# AT32UC3L0128 device description
Architecture: AVR32_UC3; Family: AVR UC3
Registers are 32-bit, read-write, reset 0x0 unless marked. A register's access mark holds for its fields unless they carry their own. Offsets are from the block's base; [hi:lo] are bit positions; {n}, {i} and the like mark numbered series; 'fields as' and 'values as' point back to an identical list.

## SCIF — System Control Interface
Instances: SCIF 0xffff1800
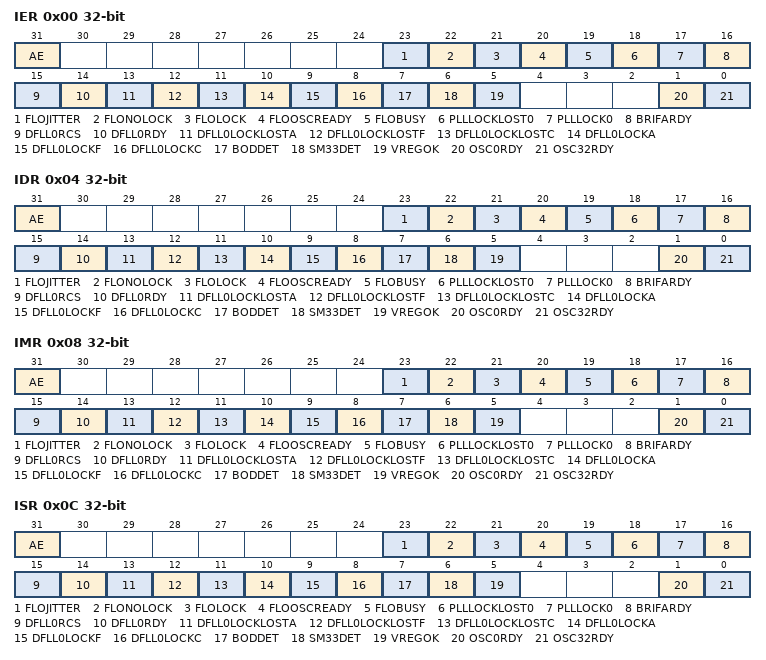
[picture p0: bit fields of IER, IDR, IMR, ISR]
0x00 IER wo — Interrupt Enable Register
  [31] AE, [23] FLOJITTER, [22] FLONOLOCK, [21] FLOLOCK, [20] FLOOSCREADY, [19] FLOBUSY, [18] PLLLOCKLOST0, [17] PLLLOCK0, [16] BRIFARDY, [15] DFLL0RCS, [14] DFLL0RDY, [13] DFLL0LOCKLOSTA, [12] DFLL0LOCKLOSTF, [11] DFLL0LOCKLOSTC, [10] DFLL0LOCKA, [9] DFLL0LOCKF, [8] DFLL0LOCKC, [7] BODDET, [6] SM33DET, [5] VREGOK, [1] OSC0RDY, [0] OSC32RDY
0x04 IDR wo — Interrupt Disable Register
  fields as IER
0x08 IMR ro — Interrupt Mask Register
  fields as IER
0x0C ISR ro — Interrupt Status Register
  fields as IER
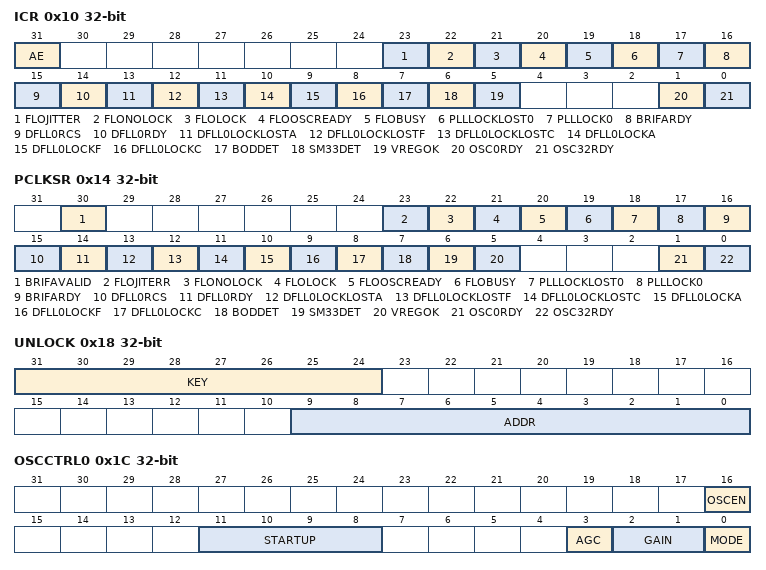
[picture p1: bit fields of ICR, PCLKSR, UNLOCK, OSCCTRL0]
0x10 ICR wo — Interrupt Clear Register
  fields as IER
0x14 PCLKSR ro — Power and Clocks Status Register
  [30] BRIFAVALID, [23] FLOJITERR, [22] FLONOLOCK, [21] FLOLOCK, [20] FLOOSCREADY, [19] FLOBUSY, [18] PLLLOCKLOST0, [17] PLLLOCK0, [16] BRIFARDY, [15] DFLL0RCS, [14] DFLL0RDY, [13] DFLL0LOCKLOSTA, [12] DFLL0LOCKLOSTF, [11] DFLL0LOCKLOSTC, [10] DFLL0LOCKA, [9] DFLL0LOCKF, [8] DFLL0LOCKC, [7] BODDET, [6] SM33DET, [5] VREGOK, [1] OSC0RDY, [0] OSC32RDY
0x18 UNLOCK wo
  [31:24] KEY — Unlock Key
    170=VALUE
  [9:0] ADDR — Unlock Address
0x1C OSCCTRL0 — Oscillator Control Register
  [16] OSCEN — Oscillator Enable
  [11:8] STARTUP — Oscillator Start-up Time
    0=0_RCOSC; 1=64_RCOSC; 2=128_RCOSC; 3=2048_RCOSC; 4=4096_RCOSC; 5=8192_RCOSC; 6=16384_RCOSC; 7=32768_RCOSC; 8=4_RCOSC; 9=8_RCOSC; 10=16_RCOSC; 11=32_RCOSC; 12=256_RCOSC; 13=512_RCOSC; 14=1024_RCOSC
  [3] AGC — Automatic Gain Control
  [2:1] GAIN
    {v}=G{v} (v=0..3)
  [0] MODE — Oscillator Mode
    0=EXT_CLOCK; 1=CRYSTAL
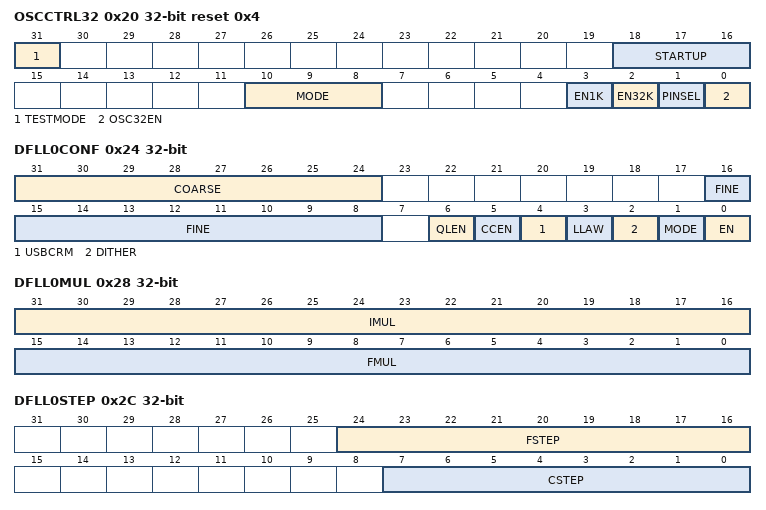
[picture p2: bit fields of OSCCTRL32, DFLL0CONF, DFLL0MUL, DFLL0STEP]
0x20 OSCCTRL32 reset 0x4 — Oscillator 32 Control Register
  [31] TESTMODE — Enable 32KHz oscillator test mode
  [18:16] STARTUP — Oscillator Start-up Time
    0=0_RCOSC; 1=128_RCOSC; 2=8192_RCOSC; 3=16384_RCOSC; 4=65536_RCOSC; 5=131072_RCOSC; 6=262144_RCOSC; 7=524288_RCOSC
  [10:8] MODE — Oscillator Mode
    0=EXT_CLOCK; 1=CRYSTAL; 4=CRYSTAL_HIC
  [3] EN1K — 1KHz Output Enable
  [2] EN32K — 32KHz Output Enable
  [1] PINSEL — Pins Select
  [0] OSC32EN — 32KHz Oscillator Enable
0x24 DFLL0CONF — DFLL0 Config Register
  [31:24] COARSE — Coarse Calibration Value
  [16:8] FINE — Fine Calibration Value
  [6] QLEN — Quick Lock Enable
  [5] CCEN — Carence Cycle Enable
  [4] USBCRM — USB Clock Recovery Mode
  [3] LLAW — Lose Lock After Wake
  [2] DITHER — Enable Dithering
  [1] MODE — Mode Selection
  [0] EN — Enable
0x28 DFLL0MUL — DFLL0 Multiplier Register
  [31:16] IMUL — DFLL Integer Multiply Factor
  [15:0] FMUL — DFLL Fractional Multiply Factor
0x2C DFLL0STEP
  [24:16] FSTEP — Fine Maximum Step
  [7:0] CSTEP — Coarse Maximum Step
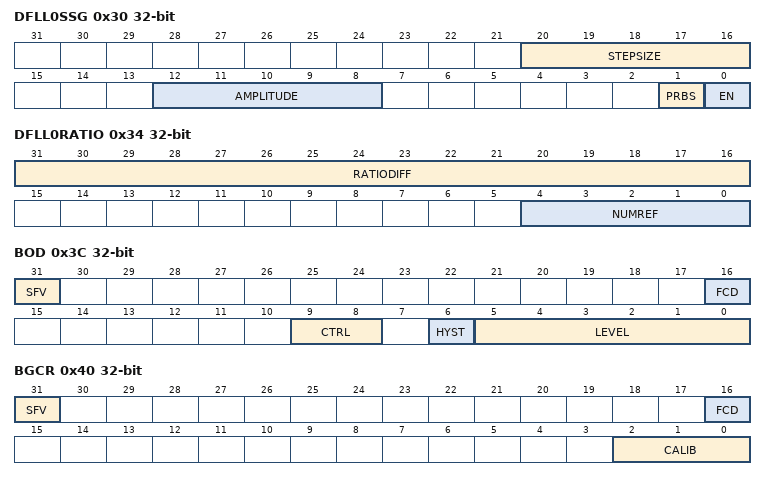
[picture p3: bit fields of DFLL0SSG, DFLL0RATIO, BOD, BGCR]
0x30 DFLL0SSG — DFLL0 Spread Spectrum Generator Control Register
  [20:16] STEPSIZE — SSG Step Size
  [12:8] AMPLITUDE — SSG Amplitude
  [1] PRBS — Pseudo Random Bit Sequence
  [0] EN — Enable
0x34 DFLL0RATIO ro — DFLL0 Ratio Registe
  [31:16] RATIODIFF — Multiplication Ratio Difference
  [4:0] NUMREF — Numerical Reference
0x38 DFLL0SYNC wo — DFLL0 Synchronization Register
  [0] SYNC — Synchronization
0x3C BOD reset not defined — BOD Control Register
  [31] SFV — Store Final Value
  [16] FCD — Fuse Calibration Done
  [9:8] CTRL — BOD Control
    0=DISABLED; 1=ENABLED; 2=ENABLED_NORESET
  [6] HYST — BOD Hysteresis
  [5:0] LEVEL — BOD Level
0x40 BGCR reset not defined — Bandgap Calibration Register
  [31] SFV — Stor Final Value
  [16] FCD — Flash Calibration Done
  [2:0] CALIB — Calibration Value
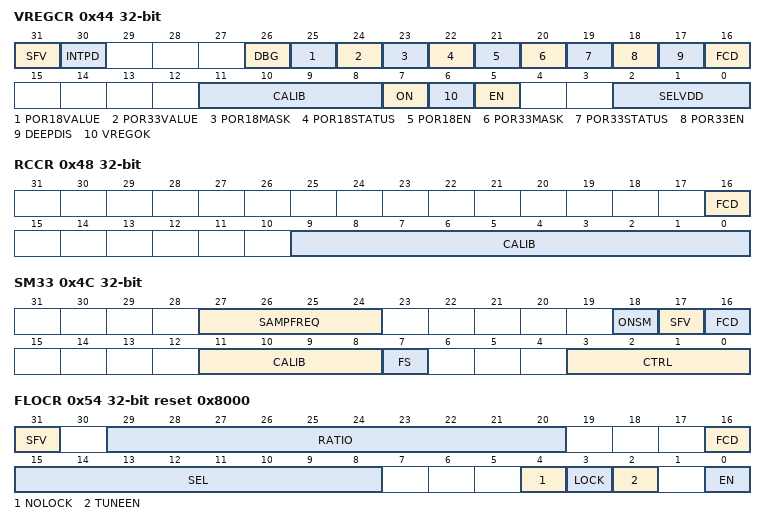
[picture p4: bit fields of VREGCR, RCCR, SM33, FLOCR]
0x44 VREGCR reset not defined — Voltage Regulator Calibration Register
  [31] SFV — Store Final Value
  [30] INTPD — Internal Pulldown
  [26] DBG — Debug session
  [25] POR18VALUE — Power-On Reset 1.8V Value
  [24] POR33VALUE — Power-On Reset 3.3V Value
  [23] POR18MASK — Power-On Reset 1.8V Output Mask
  [22] POR18STATUS — Power-On Reset 1.8V Status
  [21] POR18EN — Power-On Reset 1.8V Enable
  [20] POR33MASK — Power-On Reset 3.3V Output Mask
  [19] POR33STATUS — Power-On Reset 3.3V Status
  [18] POR33EN — Power-On Reset 3.3V Enable
  [17] DEEPDIS — Disable Regulator Deep Mode
  [16] FCD — Flash Calibration Done
  [11:8] CALIB — Calibration Value
  [7] ON — Voltage Regulator On Status
  [6] VREGOK — Voltage Regulator OK Status
  [5] EN — Enable
  [2:0] SELVDD — Select VDD
0x48 RCCR reset not defined — System RC Oscillator Calibration Register
  [16] FCD — Flash Calibration Done
  [9:0] CALIB — Calibration Value
0x4C SM33 reset not defined — Supply Monitor 33 Calibration Register
  [27:24] SAMPFREQ — Sampling Frequency
  [18] ONSM — Supply Monitor On Indicator
  [17] SFV — Store Final Value
  [16] FCD — Fuse Calibration Done
  [11:8] CALIB — Calibration Value
  [7] FS — Force Sampling Mode
  [3:0] CTRL — Supply Monitor Control
    0=DISABLED1; 1=ENABLED; 2=ENABLED_NORESET; 3=DISABLED2
0x50 TSENS — Temperature Sensor Configuration Register
  [0] EN — Temperature Sensor Enable
0x54 FLOCR reset 0x8000 — Frequency Locked Oscillator Configuration Register
  [31] SFV — Store Final Value
  [29:20] RATIO
  [16] FCD — FLO Fuse Calibration Done
  [15:8] SEL — Select
  [4] NOLOCK
  [3] LOCK
  [2] TUNEEN — Tuner Enable
  [0] EN — Enable
0x58 RC120MCR — 120 MHz RC Oscillator Control Register
  [0] EN — RC120M Enable
{0x5C+4i} BR{i} (i=0..3) — Backup Register {i}
0x6C RC32KCR — 32 kHz RC Oscillator Control Register
  [0] EN — RC32K Enable
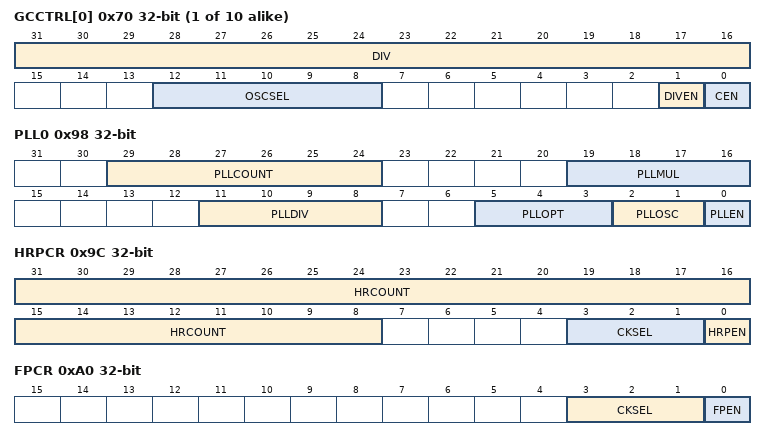
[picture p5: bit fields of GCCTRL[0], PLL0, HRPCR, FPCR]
{0x70+4i} GCCTRL[{i}] (i=0..9) — Generic Clock Control
  [31:16] DIV — Division Factor
  [12:8] OSCSEL — Clock Select
  [1] DIVEN — Divide Enable
    0=NO_DIV_CLOCK; 1=DIV_CLOCK
  [0] CEN — Clock Enable
0x98 PLL0 — PLL0 Control Register
  [29:24] PLLCOUNT
  [19:16] PLLMUL — PLL Multiply Factor
  [11:8] PLLDIV — PLL Division Factor
  [5:3] PLLOPT — PLL Option
  [2:1] PLLOSC — PLL Oscillator Select
    0=OSC0; 1=GCLK8
  [0] PLLEN — PLL Enable
0x9C HRPCR reset not defined — High Resolution Prescaler Control Register
  [31:8] HRCOUNT — High Resolution Counter
  [3:1] CKSEL — Clock Input Selection
  [0] HRPEN — High Resolution Prescaler Enable
0xA0 FPCR reset not defined — Fractional Prescaler Control Register
  [3:1] CKSEL — Clock Input Selection
  [0] FPEN — High Resolution Prescaler Enable
0xA4 FPMUL reset not defined — Fractional Prescaler Multiplier Register
  [15:0] FPMUL — Fractional Prescaler Multiplication Factor
0xA8 FPDIV reset not defined — Fractional Prescaler DIVIDER Register
  [15:0] FPDIV — Fractional Prescaler Division Factor
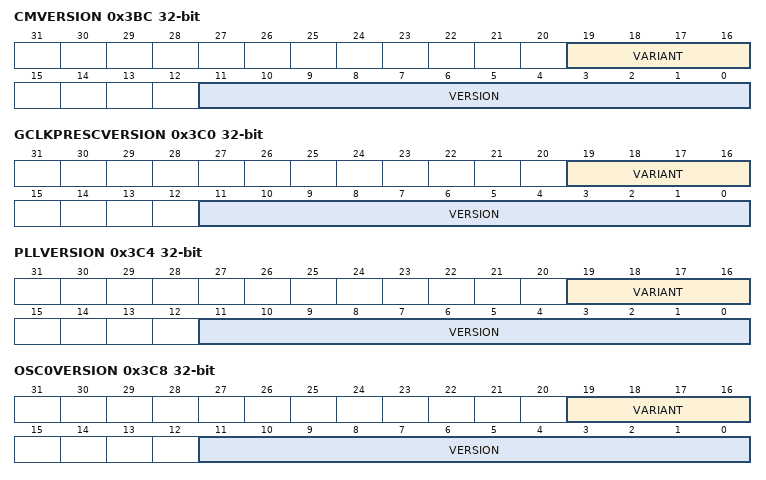
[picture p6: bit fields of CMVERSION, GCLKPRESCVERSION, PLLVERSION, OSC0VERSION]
0x3BC CMVERSION ro reset not defined — Commonly used Modules Version Register
  [19:16] VARIANT — Variant number
  [11:0] VERSION — Version number
0x3C0 GCLKPRESCVERSION ro reset not defined — Generic Clock Prescaler Version Register
  [19:16] VARIANT — Variant number
  [11:0] VERSION — Version number
0x3C4 PLLVERSION ro reset not defined
  [19:16] VARIANT — Variant nubmer
  [11:0] VERSION — Version number
0x3C8 OSC0VERSION ro reset not defined — Oscillator 0 Version Register
  [19:16] VARIANT — Variant nubmer
  [11:0] VERSION — Version number
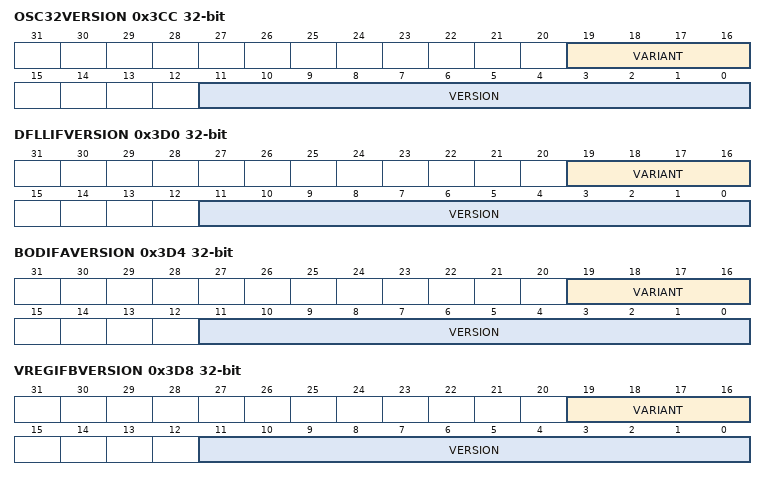
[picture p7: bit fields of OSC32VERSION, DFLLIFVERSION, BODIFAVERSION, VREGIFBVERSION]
0x3CC OSC32VERSION ro reset not defined — 32 KHz Oscillator Version Register
  [19:16] VARIANT — Variant nubmer
  [11:0] VERSION — Version number
0x3D0 DFLLIFVERSION ro reset not defined — DFLL Version Register
  [19:16] VARIANT — Variant number
  [11:0] VERSION — Version number
0x3D4 BODIFAVERSION ro reset not defined — BOD Version Register
  [19:16] VARIANT — Variant number
  [11:0] VERSION — Version number
0x3D8 VREGIFBVERSION ro reset not defined — Voltage Regulator Version Register
  [19:16] VARIANT — Variant number
  [11:0] VERSION — Version number
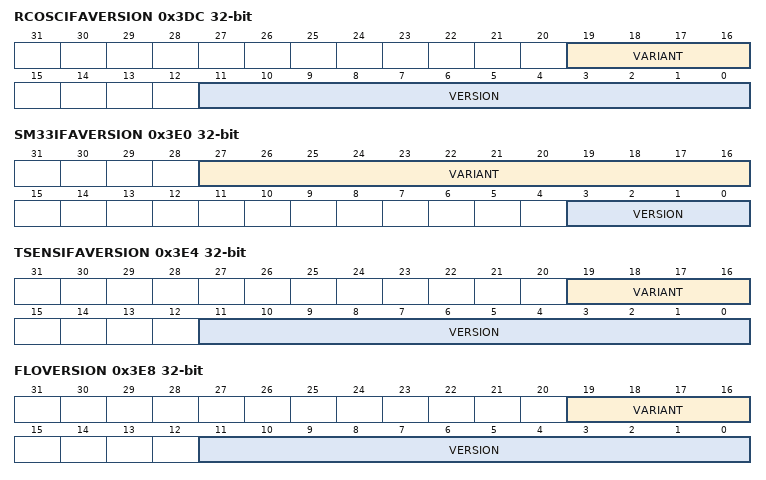
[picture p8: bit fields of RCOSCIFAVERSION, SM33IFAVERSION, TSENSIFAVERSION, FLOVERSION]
0x3DC RCOSCIFAVERSION ro reset not defined — System RC Oscillator Version Register
  [19:16] VARIANT — Variant number
  [11:0] VERSION — Version number
0x3E0 SM33IFAVERSION ro reset not defined — 3.3V Supply Monitor Version Register
  [27:16] VARIANT — Variant number
  [3:0] VERSION — Version number
0x3E4 TSENSIFAVERSION ro reset not defined — Temperature Sensor Version Register
  [19:16] VARIANT — Variant number
  [11:0] VERSION — Version number
0x3E8 FLOVERSION ro reset not defined — Frequency Locked Oscillator Version Register
  [19:16] VARIANT — Variant number
  [11:0] VERSION — Version number
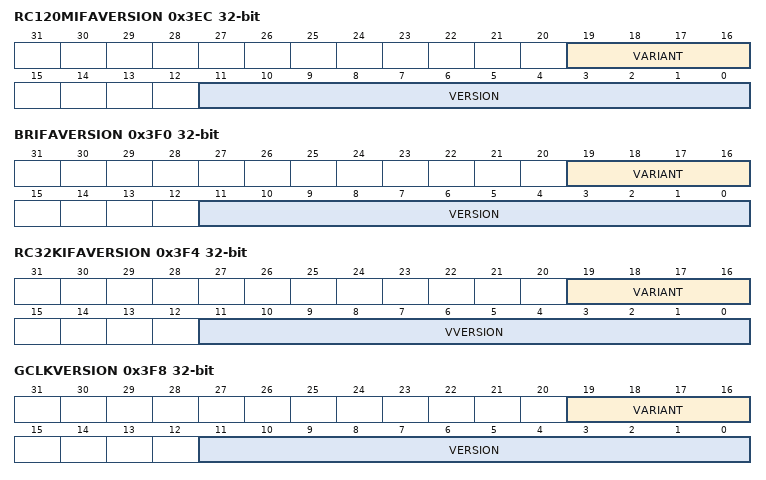
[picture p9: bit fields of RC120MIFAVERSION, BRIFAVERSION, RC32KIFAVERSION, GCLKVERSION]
0x3EC RC120MIFAVERSION ro reset not defined — 120 MHz RC Oscillator Version Register
  [19:16] VARIANT — Variant number
  [11:0] VERSION — Version number
0x3F0 BRIFAVERSION ro reset not defined — Backup Register Interface Version Register
  [19:16] VARIANT — Variant number
  [11:0] VERSION — Version number
0x3F4 RC32KIFAVERSION ro reset not defined — 32 kHz RC Oscillator Version Register
  [19:16] VARIANT — Variant number
  [11:0] VVERSION — Version number
0x3F8 GCLKVERSION ro reset not defined — Generic Clock Version Register
  [19:16] VARIANT — Variant number
  [11:0] VERSION — Version number
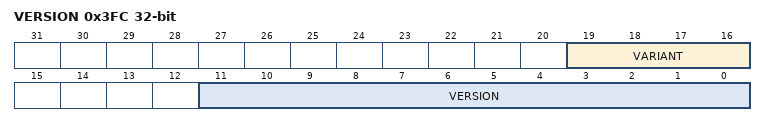
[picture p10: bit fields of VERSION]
0x3FC VERSION ro reset not defined — SCIF Version Register
  [19:16] VARIANT — Variant number
  [11:0] VERSION — Version number
